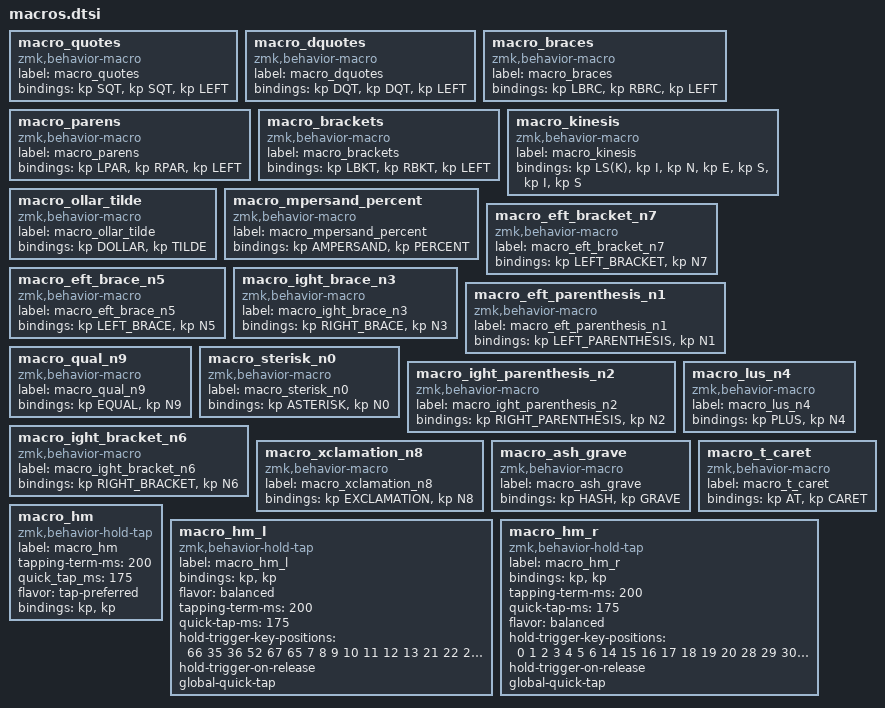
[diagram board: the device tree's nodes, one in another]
macro_quotes: macro_quotes{
compatible = "zmk,behavior-macro";
label = "macro_quotes";
#binding-cells = <0>;
bindings = <&kp SQT>, <&kp SQT>, <&kp LEFT>;
};
macro_dquotes: macro_dquotes{
compatible = "zmk,behavior-macro";
label = "macro_dquotes";
#binding-cells = <0>;
bindings = <&kp DQT>, <&kp DQT>, <&kp LEFT>;
};
macro_braces: macro_braces{
compatible = "zmk,behavior-macro";
label = "macro_braces";
#binding-cells = <0>;
bindings = <&kp LBRC>, <&kp RBRC>, <&kp LEFT>;
};
macro_parens: macro_parens{
compatible = "zmk,behavior-macro";
label = "macro_parens";
#binding-cells = <0>;
bindings = <&kp LPAR>, <&kp RPAR>, <&kp LEFT>;
};
macro_brackets: macro_brackets{
compatible = "zmk,behavior-macro";
label = "macro_brackets";
#binding-cells = <0>;
bindings = <&kp LBKT>, <&kp RBKT>, <&kp LEFT>;
};
macro_kinesis: macro_kinesis{
compatible = "zmk,behavior-macro";
label = "macro_kinesis";
#binding-cells = <0>;
bindings = <&kp LS(K)>, <&kp I>, <&kp N>, <&kp E>, <&kp S>, <&kp I>, <&kp S>;
};
macro_ollar_tilde: macro_ollar_tilde{
compatible = "zmk,behavior-macro";
label = "macro_ollar_tilde";
#binding-cells = <0>;
bindings = <&kp DOLLAR>, <&kp TILDE>;
};
macro_mpersand_percent: macro_mpersand_percent{
compatible = "zmk,behavior-macro";
label = "macro_mpersand_percent";
#binding-cells = <0>;
bindings = <&kp AMPERSAND>, <&kp PERCENT>;
};
macro_eft_bracket_n7: macro_eft_bracket_n7{
compatible = "zmk,behavior-macro";
label = "macro_eft_bracket_n7";
#binding-cells = <0>;
bindings = <&kp LEFT_BRACKET>, <&kp N7>;
};
macro_eft_brace_n5: macro_eft_brace_n5{
compatible = "zmk,behavior-macro";
label = "macro_eft_brace_n5";
#binding-cells = <0>;
bindings = <&kp LEFT_BRACE>, <&kp N5>;
};
macro_ight_brace_n3: macro_ight_brace_n3{
compatible = "zmk,behavior-macro";
label = "macro_ight_brace_n3";
#binding-cells = <0>;
bindings = <&kp RIGHT_BRACE>, <&kp N3>;
};
macro_eft_parenthesis_n1: macro_eft_parenthesis_n1{
compatible = "zmk,behavior-macro";
label = "macro_eft_parenthesis_n1";
#binding-cells = <0>;
bindings = <&kp LEFT_PARENTHESIS>, <&kp N1>;
};
macro_qual_n9: macro_qual_n9{
compatible = "zmk,behavior-macro";
label = "macro_qual_n9";
#binding-cells = <0>;
bindings = <&kp EQUAL>, <&kp N9>;
};
macro_sterisk_n0: macro_sterisk_n0{
compatible = "zmk,behavior-macro";
label = "macro_sterisk_n0";
#binding-cells = <0>;
bindings = <&kp ASTERISK>, <&kp N0>;
};
macro_ight_parenthesis_n2: macro_ight_parenthesis_n2{
compatible = "zmk,behavior-macro";
label = "macro_ight_parenthesis_n2";
#binding-cells = <0>;
bindings = <&kp RIGHT_PARENTHESIS>, <&kp N2>;
};
macro_lus_n4: macro_lus_n4{
compatible = "zmk,behavior-macro";
label = "macro_lus_n4";
#binding-cells = <0>;
bindings = <&kp PLUS>, <&kp N4>;
};
macro_ight_bracket_n6: macro_ight_bracket_n6{
compatible = "zmk,behavior-macro";
label = "macro_ight_bracket_n6";
#binding-cells = <0>;
bindings = <&kp RIGHT_BRACKET>, <&kp N6>;
};
macro_xclamation_n8: macro_xclamation_n8{
compatible = "zmk,behavior-macro";
label = "macro_xclamation_n8";
#binding-cells = <0>;
bindings = <&kp EXCLAMATION>, <&kp N8>;
};
macro_ash_grave: macro_ash_grave{
compatible = "zmk,behavior-macro";
label = "macro_ash_grave";
#binding-cells = <0>;
bindings = <&kp HASH>, <&kp GRAVE>;
};
macro_t_caret: macro_t_caret{
compatible = "zmk,behavior-macro";
label = "macro_t_caret";
#binding-cells = <0>;
bindings = <&kp AT>, <&kp CARET>;
};
macro_hm: macro_hm{
compatible = "zmk,behavior-hold-tap";
label = "macro_hm";
#binding-cells = <2>;
tapping-term-ms = <200>;
quick_tap_ms = <175>;
flavor = "tap-preferred";
bindings = <&kp>, <&kp>;
};
macro_hm_l: macro_hm_l{
compatible = "zmk,behavior-hold-tap";
label = "macro_hm_l";
bindings = <&kp>, <&kp>;
#binding-cells = <2>;
flavor = "balanced";
tapping-term-ms = <200>;
quick-tap-ms = <175>;
hold-trigger-key-positions = <66 35 36 52 67 65 7 8 9 10 11 12 13 21 22 23 24 25 26 27 38 39 40 41 42 43 44 45 54 55 56 57 58 59 70 71 72 73 74 75 37 53 69 68>;
hold-trigger-on-release;
global-quick-tap;
};
macro_hm_r: macro_hm_r{
compatible = "zmk,behavior-hold-tap";
label = "macro_hm_r";
bindings = <&kp>, <&kp>;
#binding-cells = <2>;
tapping-term-ms = <200>;
quick-tap-ms = <175>;
flavor = "balanced";
hold-trigger-key-positions = <0 1 2 3 4 5 6 14 15 16 17 18 19 20 28 29 30 31 32 33 34 35 36 46 47 48 49 50 51 52 60 61 62 63 64 65 66 67 37 38 53 68 69 70>;
hold-trigger-on-release;
global-quick-tap;
};
